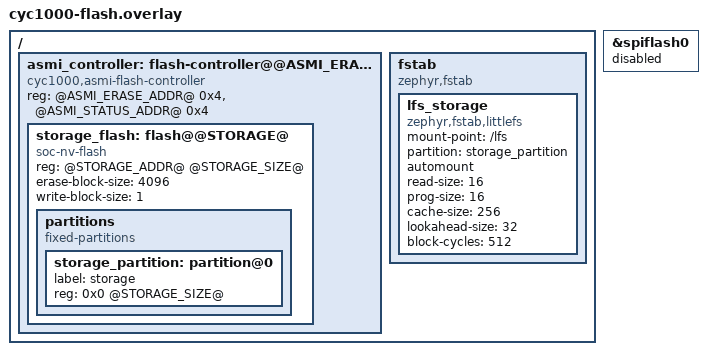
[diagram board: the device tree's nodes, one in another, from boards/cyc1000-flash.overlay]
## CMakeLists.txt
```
# SPDX-License-Identifier: Apache-2.0

cmake_minimum_required(VERSION 3.20.0)
find_package(Zephyr REQUIRED HINTS $ENV{ZEPHYR_BASE})
project(zephyr_cyc1000)

target_sources(app PRIVATE src/main.c)
target_sources_ifdef(CONFIG_CYC1000_ASMI_FLASH app PRIVATE src/asmi_flash.c)
```

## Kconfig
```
# SPDX-License-Identifier: Apache-2.0

source "Kconfig.zephyr"

config CYC1000_ASMI_FLASH
	bool "CYC1000 ASMI storage flash driver"
	default y
	depends on DT_HAS_CYC1000_ASMI_FLASH_CONTROLLER_ENABLED
	select FLASH_HAS_DRIVER_ENABLED
	select FLASH_HAS_EXPLICIT_ERASE
	select FLASH_HAS_PAGE_LAYOUT
	help
	  Flash driver for the writable SPI flash tail exposed by the LiteX
	  ASMI storage window and erase engine.
```

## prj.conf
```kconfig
CONFIG_SERIAL=y
CONFIG_CONSOLE=y
CONFIG_UART_CONSOLE=y
CONFIG_PRINTK=y
CONFIG_SHELL=y
CONFIG_SHELL_BACKEND_SERIAL=y
CONFIG_SHELL_PROMPT_UART="cyc1000:~$ "
CONFIG_SHELL_STACK_SIZE=2048

CONFIG_NETWORKING=y
CONFIG_NET_L2_ETHERNET=y
CONFIG_NET_IPV4=y
CONFIG_NET_IPV6_PE=y
# Link-local, stable SLAAC and two temporary privacy addresses during rotation.
CONFIG_NET_IF_UNICAST_IPV6_ADDR_COUNT=4
CONFIG_NET_CONFIG_SETTINGS=y
CONFIG_NET_CONFIG_NEED_IPV4=y
CONFIG_NET_DHCPV4=y
CONFIG_NET_SHELL=y
CONFIG_ETH_LITEX_LITEETH=y
CONFIG_MDIO_LITEX_LITEETH=y
CONFIG_ETH_PHY_DRIVER=y
CONFIG_PHY_GENERIC_MII=y
CONFIG_NET_STATISTICS=y
CONFIG_NET_STATISTICS_USER_API=y
CONFIG_NET_STATISTICS_PER_INTERFACE=y
CONFIG_NET_STATISTICS_ETHERNET=y
CONFIG_OBJ_CORE=y
CONFIG_NET_SOCKETS_OBJ_CORE=y
CONFIG_NET_DEBUG_NET_PKT_ALLOC=y
CONFIG_NET_SOCKETS=y
CONFIG_NET_TCP=y
CONFIG_NET_SOCKETS_POLL_MAX=8
# LiteX CYC1000 has no hardware entropy source yet; sufficient for IPv4/ARP
# bring-up, but not for cryptographic protocols.
CONFIG_TEST_RANDOM_GENERATOR=y
CONFIG_TIMER_RANDOM_GENERATOR=y
# LittleFS automount (and a format of an empty partition) runs in POST_KERNEL
# init on the main stack; 1 KiB overflows during lfs_format.
CONFIG_MAIN_STACK_SIZE=4096
CONFIG_HEAP_MEM_POOL_SIZE=1024
CONFIG_LOG=y
# Button feedback is interactive; deferred logging can otherwise hold records
# until the logging thread gets CPU time and print them in a burst.
CONFIG_LOG_MODE_IMMEDIATE=y
CONFIG_GPIO=y
CONFIG_INPUT=y
# Deliver the gpio-keys event from its 30 ms debounce work item instead of
# queueing it for the input thread; button feedback must not wait for startup.
CONFIG_INPUT_MODE_SYNCHRONOUS=y
CONFIG_INPUT_GPIO_KEYS=y

# LittleFS in the last 256 KiB of the SPI configuration flash, mounted at /lfs.
CONFIG_FLASH=y
CONFIG_FLASH_MAP=y
CONFIG_FLASH_PAGE_LAYOUT=y
CONFIG_FILE_SYSTEM=y
CONFIG_FILE_SYSTEM_LITTLEFS=y
CONFIG_FILE_SYSTEM_SHELL=y
CONFIG_FLASH_SHELL=y
```

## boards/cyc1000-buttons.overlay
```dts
/* SPDX-License-Identifier: Apache-2.0 */

#include <zephyr/dt-bindings/gpio/gpio.h>
#include <zephyr/dt-bindings/input/input-event-codes.h>

/ {
	aliases {
		sw0 = &button0;
	};

	buttons_gpio: gpio@@BUTTONS_IN@ {
		compatible = "litex,gpio";
		reg = <@BUTTONS_IN_ADDR@ 0x4>,
		      <@BUTTONS_MODE_ADDR@ 0x4>,
		      <@BUTTONS_EDGE_ADDR@ 0x4>,
		      <@BUTTONS_EV_PENDING_ADDR@ 0x4>,
		      <@BUTTONS_EV_ENABLE_ADDR@ 0x4>;
		reg-names = "in", "irq_mode", "irq_edge", "irq_pend", "irq_en";
		gpio-controller;
		#gpio-cells = <2>;
		ngpios = <1>;
		interrupt-parent = <&intc0>;
		interrupts = <@BUTTONS_IRQ@ 1>;
		status = "okay";
	};

	buttons {
		compatible = "gpio-keys";
		debounce-interval-ms = <30>;

		button0: button_0 {
			gpios = <&buttons_gpio 0 GPIO_ACTIVE_LOW>;
			label = "CYC1000 button";
			zephyr,code = <INPUT_KEY_0>;
		};
	};
};
```

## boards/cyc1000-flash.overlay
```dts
/* SPDX-License-Identifier: Apache-2.0 */

/*
 * LittleFS in the last 256 KiB of the W25Q16 (physical 0x1c0000..0x1fffff).
 * Addresses are substituted by scripts/generate-dts-overlay.sh from csr.json.
 */
/ {
	asmi_controller: flash-controller@@ASMI_ERASE@ {
		compatible = "cyc1000,asmi-flash-controller";
		reg = <@ASMI_ERASE_ADDR@ 0x4>, <@ASMI_STATUS_ADDR@ 0x4>;
		reg-names = "erase", "status";
		#address-cells = <1>;
		#size-cells = <1>;

		storage_flash: flash@@STORAGE@ {
			compatible = "soc-nv-flash";
			reg = <@STORAGE_ADDR@ @STORAGE_SIZE@>;
			erase-block-size = <4096>;
			write-block-size = <1>;

			partitions {
				compatible = "fixed-partitions";
				#address-cells = <1>;
				#size-cells = <1>;

				storage_partition: partition@0 {
					label = "storage";
					reg = <0x0 @STORAGE_SIZE@>;
				};
			};
		};
	};

	fstab {
		compatible = "zephyr,fstab";

		lfs_storage: lfs_storage {
			compatible = "zephyr,fstab,littlefs";
			mount-point = "/lfs";
			partition = <&storage_partition>;
			automount;
			read-size = <16>;
			prog-size = <16>;
			cache-size = <256>;
			lookahead-size = <32>;
			block-cycles = <512>;
		};
	};
};

/* The LiteX base DTS describes a LiteSPI flash that this SoC does not have;
 * the configuration flash is only reachable through the ASMI hard block.
 */
&spiflash0 {
	status = "disabled";
};
```

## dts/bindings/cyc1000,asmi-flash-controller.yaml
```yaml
# SPDX-License-Identifier: Apache-2.0

description: |
  CYC1000 LiteX ASMI storage controller. The child soc-nv-flash node is the
  uncached, writable LiteX "storage" window over the SPI flash tail; the
  controller registers are the LiteX asmi_erase and asmi_status CSRs.

compatible: "cyc1000,asmi-flash-controller"

include: flash-controller.yaml

properties:
  reg:
    required: true
  reg-names:
    required: true
```

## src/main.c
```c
/* SPDX-License-Identifier: Apache-2.0 */

#include <zephyr/kernel.h>
#include <zephyr/input/input.h>
#include <zephyr/fs/fs.h>
#include <zephyr/logging/log.h>
#include <zephyr/net/socket.h>
#include <zephyr/shell/shell.h>
#include <zephyr/sys/printk.h>
#include <zephyr/version.h>

#include <errno.h>

LOG_MODULE_REGISTER(cyc1000, LOG_LEVEL_INF);

#define HTTP_PORT 80

#define LFS_NODE DT_NODELABEL(lfs_storage)
FS_FSTAB_DECLARE_ENTRY(LFS_NODE);

#define HTTP_STACK_SIZE 1536

static const char http_response[] =
	"HTTP/1.1 200 OK\r\n"
	"Content-Type: text/html; charset=utf-8\r\n"
	"Connection: close\r\n"
	"\r\n"
	"<!doctype html><html><head><title>CYC1000 Zephyr</title></head>"
	"<body><h1>CYC1000 Zephyr</h1>"
	"<p>LiteEth, UART shell and HTTP are active.</p>"
	"</body></html>\n";

static void http_server(void *p1, void *p2, void *p3)
{
	int family = POINTER_TO_INT(p1);
	ARG_UNUSED(p1);
	ARG_UNUSED(p2);
	ARG_UNUSED(p3);
	struct sockaddr_in addr4 = {
		.sin_family = AF_INET,
		.sin_port = htons(HTTP_PORT),
		.sin_addr.s_addr = htonl(INADDR_ANY),
	};
	struct sockaddr_in6 addr6 = {
		.sin6_family = AF_INET6,
		.sin6_port = htons(HTTP_PORT),
		.sin6_addr = IN6ADDR_ANY_INIT,
	};
	const struct sockaddr *addr = family == AF_INET6 ?
		(const struct sockaddr *)&addr6 : (const struct sockaddr *)&addr4;
	socklen_t addr_len = family == AF_INET6 ? sizeof(addr6) : sizeof(addr4);
	int server;

	server = zsock_socket(family, SOCK_STREAM, IPPROTO_TCP);
	if (server < 0) {
		LOG_ERR("HTTP socket failed: %d", errno);
		return;
	}

	if (zsock_bind(server, addr, addr_len) < 0 ||
	    zsock_listen(server, 1) < 0) {
		LOG_ERR("HTTP/%s listen failed: %d",
			family == AF_INET6 ? "IPv6" : "IPv4", errno);
		zsock_close(server);
		return;
	}

	LOG_INF("HTTP/%s server listening on port %d",
		family == AF_INET6 ? "IPv6" : "IPv4", HTTP_PORT);
	while (true) {
		char request[128];
		int client = zsock_accept(server, NULL, NULL);

		if (client < 0) {
			LOG_ERR("HTTP accept failed: %d", errno);
			continue;
		}

		(void)zsock_recv(client, request, sizeof(request), 0);
		(void)zsock_send(client, http_response, sizeof(http_response) - 1, 0);
		zsock_close(client);
	}
}

K_THREAD_DEFINE(http_server_v4_thread, HTTP_STACK_SIZE, http_server,
		INT_TO_POINTER(AF_INET), NULL, NULL, 7, 0, 0);
K_THREAD_DEFINE(http_server_v6_thread, HTTP_STACK_SIZE, http_server,
		INT_TO_POINTER(AF_INET6), NULL, NULL, 7, 0, 0);

static void button_event(struct input_event *evt, void *user_data)
{
	ARG_UNUSED(user_data);

	if (evt->type == INPUT_EV_KEY && evt->code == INPUT_KEY_0 && evt->value) {
		LOG_INF("CYC1000 button pressed");
	}
}

INPUT_CALLBACK_DEFINE(NULL, button_event, NULL);

static int cmd_info(const struct shell *sh, size_t argc, char **argv)
{
	ARG_UNUSED(argc);
	ARG_UNUSED(argv);

	shell_print(sh, "CYC1000: Zephyr %s", KERNEL_VERSION_STRING);
	shell_print(sh, "UART shell, LiteEth and HTTP are active.");
	return 0;
}

SHELL_CMD_REGISTER(cyc1000_info, NULL, "Show CYC1000 Zephyr configuration", cmd_info);

int main(void)
{
	int lfs_rc = fs_mount(&FS_FSTAB_ENTRY(LFS_NODE));
	if (lfs_rc && lfs_rc != -EBUSY) {
		LOG_ERR("LittleFS mount failed: %d", lfs_rc);
	} else {
		LOG_INF("LittleFS mounted at /lfs");
	}
	printk("\nCYC1000 Zephyr started. Type 'help' for the UART shell.\n");
	LOG_INF("UART logging, button input, LiteEth and HTTP are active");
	return 0;
}
```

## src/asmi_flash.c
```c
/* SPDX-License-Identifier: Apache-2.0 */

/*
 * Flash driver for the CYC1000 LiteX ASMI storage window.
 *
 * The gateware maps only the SPI flash tail at the soc-nv-flash node, so the
 * configuration image, BIOS and Zephyr boot image can not be reached from
 * here. Reads and writes are plain uncached bus accesses: the ASMI IP turns
 * every store into write enable + page program and stalls the next flash
 * access until programming completed. Erase uses the gateware engine, which
 * blocks the storage window until the flash reports idle again.
 */

#define DT_DRV_COMPAT cyc1000_asmi_flash_controller

#include <zephyr/device.h>
#include <zephyr/devicetree.h>
#include <zephyr/drivers/flash.h>
#include <zephyr/kernel.h>
#include <zephyr/logging/log.h>
#include <zephyr/sys/sys_io.h>

#include <string.h>

LOG_MODULE_REGISTER(cyc1000_asmi_flash, CONFIG_FLASH_LOG_LEVEL);

#define FLASH_NODE    DT_NODELABEL(storage_flash)
#define STORAGE_BASE  DT_REG_ADDR(FLASH_NODE)
#define STORAGE_SIZE  DT_REG_SIZE(FLASH_NODE)
#define ERASE_SIZE    DT_PROP(FLASH_NODE, erase_block_size)
#define ERASE_REG     DT_INST_REG_ADDR_BY_NAME(0, erase)
#define STATUS_REG    DT_INST_REG_ADDR_BY_NAME(0, status)

#define STATUS_BUSY   BIT(0)
/* 4 KiB subsector erase: typically 45 ms, at most 400 ms on the W25Q16. */
#define ERASE_TIMEOUT_MS 1000

static K_MUTEX_DEFINE(asmi_lock);

static const struct flash_parameters asmi_flash_parameters = {
	.write_block_size = DT_PROP(FLASH_NODE, write_block_size),
	.erase_value = 0xff,
};

#if defined(CONFIG_FLASH_PAGE_LAYOUT)
static const struct flash_pages_layout asmi_flash_layout = {
	.pages_count = STORAGE_SIZE / ERASE_SIZE,
	.pages_size = ERASE_SIZE,
};
#endif

static bool asmi_range_valid(off_t offset, size_t len)
{
	return offset >= 0 && (size_t)offset <= STORAGE_SIZE &&
	       len <= STORAGE_SIZE - (size_t)offset;
}

static int asmi_flash_read(const struct device *dev, off_t offset, void *data, size_t len)
{
	ARG_UNUSED(dev);

	if (!asmi_range_valid(offset, len)) {
		return -EINVAL;
	}

	k_mutex_lock(&asmi_lock, K_FOREVER);
	memcpy(data, (const void *)(STORAGE_BASE + offset), len);
	k_mutex_unlock(&asmi_lock);
	return 0;
}

static int asmi_flash_write(const struct device *dev, off_t offset, const void *data, size_t len)
{
	const uint8_t *src = data;
	mem_addr_t addr = STORAGE_BASE + offset;

	ARG_UNUSED(dev);

	if (!asmi_range_valid(offset, len)) {
		return -EINVAL;
	}

	/*
	 * Only aligned byte and word stores are issued: the ASMI IP supports
	 * byte-enable patterns of single bytes, halves and full words only.
	 * A word program is one flash command, so prefer words where aligned.
	 */
	k_mutex_lock(&asmi_lock, K_FOREVER);
	while (len > 0) {
		if ((addr & 3) == 0 && len >= 4) {
			uint32_t word;

			memcpy(&word, src, sizeof(word));
			sys_write32(word, addr);
			addr += 4;
			src += 4;
			len -= 4;
		} else {
			sys_write8(*src, addr);
			addr++;
			src++;
			len--;
		}
	}
	k_mutex_unlock(&asmi_lock);
	return 0;
}

static int asmi_flash_erase(const struct device *dev, off_t offset, size_t size)
{
	int rc = 0;

	ARG_UNUSED(dev);

	if (!asmi_range_valid(offset, size) || offset % ERASE_SIZE || size % ERASE_SIZE) {
		return -EINVAL;
	}

	k_mutex_lock(&asmi_lock, K_FOREVER);
	for (size_t done = 0; done < size && rc == 0; done += ERASE_SIZE) {
		int64_t deadline = k_uptime_get() + ERASE_TIMEOUT_MS;

		sys_write32(offset + done, ERASE_REG);
		/* Never touch the storage window while the engine is busy: the
		 * access would stall the CPU bus until the erase finished.
		 */
		while (sys_read32(STATUS_REG) & STATUS_BUSY) {
			if (k_uptime_get() > deadline) {
				LOG_ERR("erase at 0x%lx timed out", (long)(offset + done));
				rc = -ETIMEDOUT;
				break;
			}
			k_msleep(1);
		}
	}
	k_mutex_unlock(&asmi_lock);
	return rc;
}

static const struct flash_parameters *asmi_flash_get_parameters(const struct device *dev)
{
	ARG_UNUSED(dev);
	return &asmi_flash_parameters;
}

#if defined(CONFIG_FLASH_PAGE_LAYOUT)
static void asmi_flash_page_layout(const struct device *dev,
				   const struct flash_pages_layout **layout, size_t *layout_size)
{
	ARG_UNUSED(dev);
	*layout = &asmi_flash_layout;
	*layout_size = 1;
}
#endif

static const struct flash_driver_api asmi_flash_api = {
	.read = asmi_flash_read,
	.write = asmi_flash_write,
	.erase = asmi_flash_erase,
	.get_parameters = asmi_flash_get_parameters,
#if defined(CONFIG_FLASH_PAGE_LAYOUT)
	.page_layout = asmi_flash_page_layout,
#endif
};

DEVICE_DT_INST_DEFINE(0, NULL, NULL, NULL, NULL, POST_KERNEL,
		      CONFIG_FLASH_INIT_PRIORITY, &asmi_flash_api);
```
